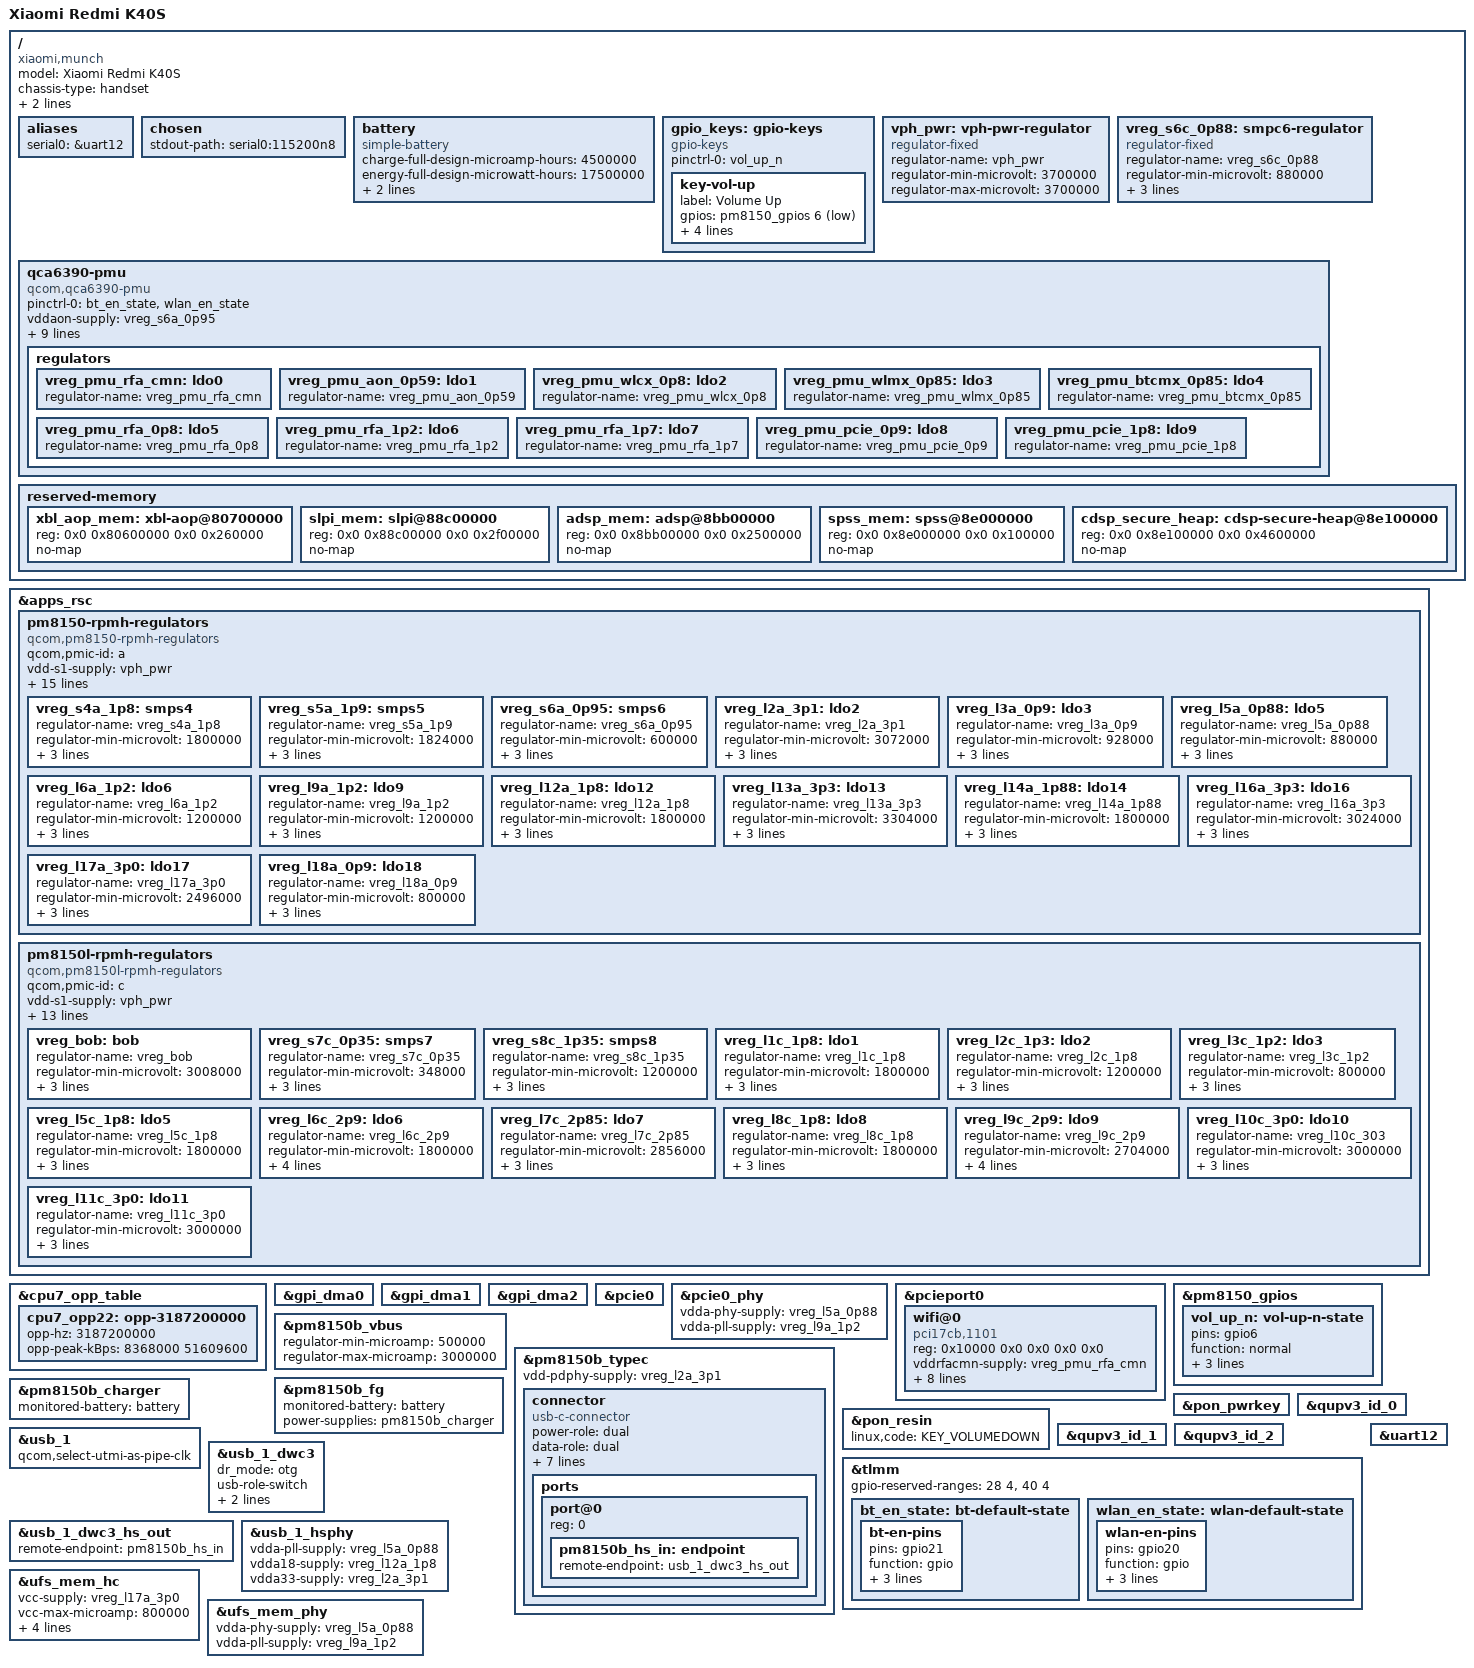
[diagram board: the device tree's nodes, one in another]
// SPDX-License-Identifier: GPL-2.0-only OR BSD-2-Clause
/*
 * Xiaomi Redmi K40S (munch) — headless server device tree
 *
 * Minimal device tree for running the K40S as a screenless Linux server:
 * only the peripherals relevant to headless operation are enabled.
 *
 *   kept:    UFS storage, USB (gadget / USB-C role switch), PCIe QCA6390 WiFi,
 *            PMIC charging + fuel gauge, volume keys, UART debug console,
 *            CPU OPP (incl. SM8250-AC boost clock), RPMH regulators.
 *   removed: display panel/DSI, touch, cameras, audio, GPU, video codec,
 *            NFC, IR LED, sensors, wireless charging, remoteproc firmware.
 *
 * Board-level values were derived from the Xiaomi POCO F3 (alioth) mainline
 * port (Copyright (c) 2025 Vitalii Skorkin) — same SM8250-AC platform and
 * PMIC wiring — and cross-checked against the LineageOS munch vendor device
 * tree (battery capacity, UFS rails, WiFi/BT enable GPIOs, AOP memory map).
 */

/dts-v1/;

#include <dt-bindings/arm/qcom,ids.h>
#include <dt-bindings/regulator/qcom,rpmh-regulator.h>
#include <dt-bindings/usb/pd.h>
#include "sm8250.dtsi"
#include "pm8150.dtsi"
#include "pm8150b.dtsi"
#include "pm8150l.dtsi"

/*
 * Delete following upstream (sm8250.dtsi) reserved
 * memory mappings which are different on this device.
 */
/delete-node/ &adsp_mem;
/delete-node/ &cdsp_secure_heap;
/delete-node/ &slpi_mem;
/delete-node/ &spss_mem;
/delete-node/ &xbl_aop_mem;

/ {

	model = "Xiaomi Redmi K40S";
	compatible = "xiaomi,munch", "qcom,sm8250";
	chassis-type = "handset";

	/* required for bootloader to select correct board */
	qcom,msm-id = <QCOM_ID_SM8250 0x20001>; /* SM8250 v2.1 */
	qcom,board-id = <50 0>;

	aliases {
		serial0 = &uart12;
	};

	chosen {
		#address-cells = <2>;
		#size-cells = <2>;
		ranges;
		stdout-path = "serial0:115200n8";
	};

	battery: battery {
		compatible = "simple-battery";
		charge-full-design-microamp-hours = <4500000>;
		energy-full-design-microwatt-hours = <17500000>;
		voltage-min-design-microvolt = <3400000>;
		voltage-max-design-microvolt = <4460000>;
	};

	gpio_keys: gpio-keys {
		compatible = "gpio-keys";

		pinctrl-0 = <&vol_up_n>;
		pinctrl-names = "default";

		key-vol-up {
			label = "Volume Up";
			gpios = <&pm8150_gpios 6 GPIO_ACTIVE_LOW>;
			linux,code = <KEY_VOLUMEUP>;
			debounce-interval = <15>;
			linux,can-disable;
			wakeup-source;
		};
	};

	vph_pwr: vph-pwr-regulator {
		compatible = "regulator-fixed";
		regulator-name = "vph_pwr";
		regulator-min-microvolt = <3700000>;
		regulator-max-microvolt = <3700000>;
	};

	/* S6c is really ebi.lvl but it's there for supply map completeness sake. */
	vreg_s6c_0p88: smpc6-regulator {
		compatible = "regulator-fixed";
		regulator-name = "vreg_s6c_0p88";
		regulator-min-microvolt = <880000>;
		regulator-max-microvolt = <880000>;
		regulator-always-on;
		vin-supply = <&vph_pwr>;
	};

	qca6390-pmu {
		compatible = "qcom,qca6390-pmu";

		pinctrl-names = "default";
		pinctrl-0 = <&bt_en_state>, <&wlan_en_state>;

		vddaon-supply = <&vreg_s6a_0p95>;
		vddpmu-supply = <&vreg_s6a_0p95>;
		vddrfa0p95-supply = <&vreg_s6a_0p95>;
		vddrfa1p3-supply = <&vreg_s8c_1p35>;
		vddrfa1p9-supply = <&vreg_s5a_1p9>;
		vddpcie1p3-supply = <&vreg_s8c_1p35>;
		vddpcie1p9-supply = <&vreg_s5a_1p9>;
		vddio-supply = <&vreg_s4a_1p8>;

		wlan-enable-gpios = <&tlmm 20 GPIO_ACTIVE_HIGH>;
		bt-enable-gpios = <&tlmm 21 GPIO_ACTIVE_HIGH>;

		regulators {
			vreg_pmu_rfa_cmn: ldo0 {
				regulator-name = "vreg_pmu_rfa_cmn";
			};

			vreg_pmu_aon_0p59: ldo1 {
				regulator-name = "vreg_pmu_aon_0p59";
			};

			vreg_pmu_wlcx_0p8: ldo2 {
				regulator-name = "vreg_pmu_wlcx_0p8";
			};

			vreg_pmu_wlmx_0p85: ldo3 {
				regulator-name = "vreg_pmu_wlmx_0p85";
			};

			vreg_pmu_btcmx_0p85: ldo4 {
				regulator-name = "vreg_pmu_btcmx_0p85";
			};

			vreg_pmu_rfa_0p8: ldo5 {
				regulator-name = "vreg_pmu_rfa_0p8";
			};

			vreg_pmu_rfa_1p2: ldo6 {
				regulator-name = "vreg_pmu_rfa_1p2";
			};

			vreg_pmu_rfa_1p7: ldo7 {
				regulator-name = "vreg_pmu_rfa_1p7";
			};

			vreg_pmu_pcie_0p9: ldo8 {
				regulator-name = "vreg_pmu_pcie_0p9";
			};

			vreg_pmu_pcie_1p8: ldo9 {
				regulator-name = "vreg_pmu_pcie_1p8";
			};
		};
	};

	reserved-memory {
		xbl_aop_mem: xbl-aop@80700000 {
			reg = <0x0 0x80600000 0x0 0x260000>;
			no-map;
		};

		slpi_mem: slpi@88c00000 {
			reg = <0x0 0x88c00000 0x0 0x2f00000>;
			no-map;
		};

		adsp_mem: adsp@8bb00000 {
			reg = <0x0 0x8bb00000 0x0 0x2500000>;
			no-map;
		};

		spss_mem: spss@8e000000 {
			reg = <0x0 0x8e000000 0x0 0x100000>;
			no-map;
		};

		cdsp_secure_heap: cdsp-secure-heap@8e100000 {
			reg = <0x0 0x8e100000 0x0 0x4600000>;
			no-map;
		};
	};
};

/*
 * RPMH regulators: platform wiring shared by Xiaomi SM8250 boards.
 * Kept in full — these rails are consumed by UFS, USB, PCIe/WiFi,
 * the QCA6390 PMU tree and the PMIC charger.
 */
&apps_rsc {
	pm8150-rpmh-regulators {
		compatible = "qcom,pm8150-rpmh-regulators";
		qcom,pmic-id = "a";

		vdd-s1-supply = <&vph_pwr>;
		vdd-s2-supply = <&vph_pwr>;
		vdd-s3-supply = <&vph_pwr>;
		vdd-s4-supply = <&vph_pwr>;
		vdd-s5-supply = <&vph_pwr>;
		vdd-s6-supply = <&vph_pwr>;
		vdd-s7-supply = <&vph_pwr>;
		vdd-s8-supply = <&vph_pwr>;
		vdd-s9-supply = <&vph_pwr>;
		vdd-s10-supply = <&vph_pwr>;
		vdd-l1-l8-l11-supply = <&vreg_s6c_0p88>;
		vdd-l2-l10-supply = <&vreg_bob>;
		vdd-l3-l4-l5-l18-supply = <&vreg_s6a_0p95>;
		vdd-l6-l9-supply = <&vreg_s8c_1p35>;
		vdd-l7-l12-l14-l15-supply = <&vreg_s5a_1p9>;
		vdd-l13-l16-l17-supply = <&vreg_bob>;

		/* (S1+S2+S3) - cx.lvl (ARC) */

		vreg_s4a_1p8: smps4 {
			regulator-name = "vreg_s4a_1p8";
			regulator-min-microvolt = <1800000>;
			regulator-max-microvolt = <1920000>;
			regulator-initial-mode = <RPMH_REGULATOR_MODE_HPM>;
		};

		vreg_s5a_1p9: smps5 {
			regulator-name = "vreg_s5a_1p9";
			regulator-min-microvolt = <1824000>;
			regulator-max-microvolt = <2040000>;
			regulator-initial-mode = <RPMH_REGULATOR_MODE_HPM>;
		};

		vreg_s6a_0p95: smps6 {
			regulator-name = "vreg_s6a_0p95";
			regulator-min-microvolt = <600000>;
			regulator-max-microvolt = <1128000>;
			regulator-initial-mode = <RPMH_REGULATOR_MODE_HPM>;
		};

		vreg_l2a_3p1: ldo2 {
			regulator-name = "vreg_l2a_3p1";
			regulator-min-microvolt = <3072000>;
			regulator-max-microvolt = <3072000>;
			regulator-initial-mode = <RPMH_REGULATOR_MODE_HPM>;
		};

		vreg_l3a_0p9: ldo3 {
			regulator-name = "vreg_l3a_0p9";
			regulator-min-microvolt = <928000>;
			regulator-max-microvolt = <932000>;
			regulator-initial-mode = <RPMH_REGULATOR_MODE_HPM>;
		};

		/* L4 - lmx.lvl (ARC) */

		vreg_l5a_0p88: ldo5 {
			regulator-name = "vreg_l5a_0p88";
			regulator-min-microvolt = <880000>;
			regulator-max-microvolt = <880000>;
			regulator-initial-mode = <RPMH_REGULATOR_MODE_HPM>;
		};

		vreg_l6a_1p2: ldo6 {
			regulator-name = "vreg_l6a_1p2";
			regulator-min-microvolt = <1200000>;
			regulator-max-microvolt = <1200000>;
			regulator-initial-mode = <RPMH_REGULATOR_MODE_HPM>;
		};

		vreg_l9a_1p2: ldo9 {
			regulator-name = "vreg_l9a_1p2";
			regulator-min-microvolt = <1200000>;
			regulator-max-microvolt = <1200000>;
			regulator-initial-mode = <RPMH_REGULATOR_MODE_HPM>;
		};

		vreg_l12a_1p8: ldo12 {
			regulator-name = "vreg_l12a_1p8";
			regulator-min-microvolt = <1800000>;
			regulator-max-microvolt = <1800000>;
			regulator-initial-mode = <RPMH_REGULATOR_MODE_HPM>;
		};

		vreg_l13a_3p3: ldo13 {
			regulator-name = "vreg_l13a_3p3";
			regulator-min-microvolt = <3304000>;
			regulator-max-microvolt = <3304000>;
			regulator-initial-mode = <RPMH_REGULATOR_MODE_HPM>;
		};

		vreg_l14a_1p88: ldo14 {
			regulator-name = "vreg_l14a_1p88";
			regulator-min-microvolt = <1800000>;
			regulator-max-microvolt = <1880000>;
			regulator-initial-mode = <RPMH_REGULATOR_MODE_HPM>;
		};

		vreg_l16a_3p3: ldo16 {
			regulator-name = "vreg_l16a_3p3";
			regulator-min-microvolt = <3024000>;
			regulator-max-microvolt = <3304000>;
			regulator-initial-mode = <RPMH_REGULATOR_MODE_HPM>;
		};

		vreg_l17a_3p0: ldo17 {
			regulator-name = "vreg_l17a_3p0";
			regulator-min-microvolt = <2496000>;
			regulator-max-microvolt = <3008000>;
			regulator-initial-mode = <RPMH_REGULATOR_MODE_HPM>;
		};

		vreg_l18a_0p9: ldo18 {
			regulator-name = "vreg_l18a_0p9";
			regulator-min-microvolt = <800000>;
			regulator-max-microvolt = <920000>;
			regulator-initial-mode = <RPMH_REGULATOR_MODE_HPM>;
		};
	};

	pm8150l-rpmh-regulators {
		compatible = "qcom,pm8150l-rpmh-regulators";
		qcom,pmic-id = "c";

		vdd-s1-supply = <&vph_pwr>;
		vdd-s2-supply = <&vph_pwr>;
		vdd-s3-supply = <&vph_pwr>;
		vdd-s4-supply = <&vph_pwr>;
		vdd-s5-supply = <&vph_pwr>;
		vdd-s6-supply = <&vph_pwr>;
		vdd-s7-supply = <&vph_pwr>;
		vdd-s8-supply = <&vph_pwr>;
		vdd-l1-l8-supply = <&vreg_s4a_1p8>;
		vdd-l2-l3-supply = <&vreg_s8c_1p35>;
		vdd-l4-l5-l6-supply = <&vreg_bob>;
		vdd-l7-l11-supply = <&vreg_bob>;
		vdd-l9-l10-supply = <&vreg_bob>;
		vdd-bob-supply = <&vph_pwr>;

		vreg_bob: bob {
			regulator-name = "vreg_bob";
			regulator-min-microvolt = <3008000>;
			regulator-max-microvolt = <3960000>;
			regulator-initial-mode = <RPMH_REGULATOR_MODE_AUTO>;
		};

		/*
		 * S1-S6 are ARCs:
		 * (S1+S2) - gfx.lvl,
		 * S3 - mx.lvl,
		 * (S4+S5) - mmcx.lvl,
		 * S6 - ebi.lvl
		 */

		vreg_s7c_0p35: smps7 {
			regulator-name = "vreg_s7c_0p35";
			regulator-min-microvolt = <348000>;
			regulator-max-microvolt = <1000000>;
			regulator-initial-mode = <RPMH_REGULATOR_MODE_HPM>;
		};

		vreg_s8c_1p35: smps8 {
			regulator-name = "vreg_s8c_1p35";
			regulator-min-microvolt = <1200000>;
			regulator-max-microvolt = <1400000>;
			regulator-initial-mode = <RPMH_REGULATOR_MODE_HPM>;
		};

		vreg_l1c_1p8: ldo1 {
			regulator-name = "vreg_l1c_1p8";
			regulator-min-microvolt = <1800000>;
			regulator-max-microvolt = <1800000>;
			regulator-initial-mode = <RPMH_REGULATOR_MODE_HPM>;
		};

		vreg_l2c_1p3: ldo2 {
			regulator-name = "vreg_l2c_1p8";
			regulator-min-microvolt = <1200000>;
			regulator-max-microvolt = <1304000>;
			regulator-initial-mode = <RPMH_REGULATOR_MODE_HPM>;
		};

		vreg_l3c_1p2: ldo3 {
			regulator-name = "vreg_l3c_1p2";
			regulator-min-microvolt = <800000>;
			regulator-max-microvolt = <1200000>;
			regulator-initial-mode = <RPMH_REGULATOR_MODE_HPM>;
		};

		vreg_l5c_1p8: ldo5 {
			regulator-name = "vreg_l5c_1p8";
			regulator-min-microvolt = <1800000>;
			regulator-max-microvolt = <2800000>;
			regulator-initial-mode = <RPMH_REGULATOR_MODE_HPM>;
		};

		vreg_l6c_2p9: ldo6 {
			regulator-name = "vreg_l6c_2p9";
			regulator-min-microvolt = <1800000>;
			regulator-max-microvolt = <2960000>;
			regulator-initial-mode = <RPMH_REGULATOR_MODE_HPM>;
			regulator-allow-set-load;
		};

		vreg_l7c_2p85: ldo7 {
			regulator-name = "vreg_l7c_2p85";
			regulator-min-microvolt = <2856000>;
			regulator-max-microvolt = <3104000>;
			regulator-initial-mode = <RPMH_REGULATOR_MODE_HPM>;
		};

		vreg_l8c_1p8: ldo8 {
			regulator-name = "vreg_l8c_1p8";
			regulator-min-microvolt = <1800000>;
			regulator-max-microvolt = <1800000>;
			regulator-initial-mode = <RPMH_REGULATOR_MODE_HPM>;
		};

		vreg_l9c_2p9: ldo9 {
			regulator-name = "vreg_l9c_2p9";
			regulator-min-microvolt = <2704000>;
			regulator-max-microvolt = <2960000>;
			regulator-initial-mode = <RPMH_REGULATOR_MODE_HPM>;
			regulator-allow-set-load;
		};

		vreg_l10c_3p0: ldo10 {
			regulator-name = "vreg_l10c_303";
			regulator-min-microvolt = <3000000>;
			regulator-max-microvolt = <3312000>;
			regulator-initial-mode = <RPMH_REGULATOR_MODE_HPM>;
		};

		vreg_l11c_3p0: ldo11 {
			regulator-name = "vreg_l11c_3p0";
			regulator-min-microvolt = <3000000>;
			regulator-max-microvolt = <3000000>;
			regulator-initial-mode = <RPMH_REGULATOR_MODE_HPM>;
		};
	};
};

/* SM8250-AC ("SD870") boost clock: 3.1872 GHz */
&cpu7_opp_table {
	cpu7_opp22: opp-3187200000 {
		opp-hz = /bits/ 64 <3187200000>;
		opp-peak-kBps = <8368000 51609600>;
	};
};

&gpi_dma0 {
	status = "okay";
};

&gpi_dma1 {
	status = "okay";
};

&gpi_dma2 {
	status = "okay";
};

/* --- WiFi: QCA6390 on PCIe0 --- */

&pcie0 {
	status = "okay";
};

&pcie0_phy {
	vdda-phy-supply = <&vreg_l5a_0p88>;
	vdda-pll-supply = <&vreg_l9a_1p2>;
	status = "okay";
};

&pcieport0 {
	wifi@0 {
		compatible = "pci17cb,1101";
		reg = <0x10000 0x0 0x0 0x0 0x0>;

		vddrfacmn-supply = <&vreg_pmu_rfa_cmn>;
		vddaon-supply = <&vreg_pmu_aon_0p59>;
		vddwlcx-supply = <&vreg_pmu_wlcx_0p8>;
		vddwlmx-supply = <&vreg_pmu_wlmx_0p85>;
		vddrfa0p8-supply = <&vreg_pmu_rfa_0p8>;
		vddrfa1p2-supply = <&vreg_pmu_rfa_1p2>;
		vddrfa1p7-supply = <&vreg_pmu_rfa_1p7>;
		vddpcie0p9-supply = <&vreg_pmu_pcie_0p9>;
		vddpcie1p8-supply = <&vreg_pmu_pcie_1p8>;
	};
};

/* --- Power / keys / charging --- */

&pm8150_gpios {
	vol_up_n: vol-up-n-state {
		pins = "gpio6";
		function = "normal";
		power-source = <1>;
		input-enable;
		bias-pull-up;
	};
};

&pm8150b_vbus {
	regulator-min-microamp = <500000>;
	regulator-max-microamp = <3000000>;
	status = "okay";
};

&pm8150b_typec {
	status = "okay";

	vdd-pdphy-supply = <&vreg_l2a_3p1>;

	connector {
		compatible = "usb-c-connector";

		power-role = "dual";
		data-role = "dual";
		try-power-role = "sink";
		self-powered;

		op-sink-microwatt = <33000000>;

		source-pdos = <PDO_FIXED(5000, 3000,
					  PDO_FIXED_DUAL_ROLE |
					  PDO_FIXED_USB_COMM |
					  PDO_FIXED_DATA_SWAP)>;

		sink-pdos = <PDO_FIXED(5000, 3000,
					   PDO_FIXED_DUAL_ROLE |
					   PDO_FIXED_USB_COMM |
					   PDO_FIXED_DATA_SWAP)
					   PDO_VAR(5000, 9000, 3500)>;

		ports {
			#address-cells = <1>;
			#size-cells = <0>;

			port@0 {
				reg = <0>;
				pm8150b_hs_in: endpoint {
					remote-endpoint = <&usb_1_dwc3_hs_out>;
				};
			};
		};
	};
};

&pm8150b_fg {
	status = "okay";
	monitored-battery = <&battery>;
	power-supplies = <&pm8150b_charger>;
};

&pm8150b_charger {
	status = "okay";
	monitored-battery = <&battery>;
};

&pon_pwrkey {
	status = "okay";
};

&pon_resin {
	linux,code = <KEY_VOLUMEDOWN>;
	status = "okay";
};

/* --- QUP wrappers (UART console on qupv3_id_1/uart12) --- */

&qupv3_id_0 {
	status = "okay";
};

&qupv3_id_1 {
	status = "okay";
};

&qupv3_id_2 {
	status = "okay";
};

/* --- TLMM: WiFi/BT enable pins --- */

&tlmm {
	gpio-reserved-ranges = <28 4>, <40 4>;

	bt_en_state: bt-default-state {
		bt-en-pins {
			pins = "gpio21";
			function = "gpio";
			drive-strength = <16>;
			output-low;
			bias-pull-up;
		};
	};

	wlan_en_state: wlan-default-state {
		wlan-en-pins {
			pins = "gpio20";
			function = "gpio";
			drive-strength = <16>;
			output-low;
			bias-pull-up;
		};
	};
};

/* --- Debug UART (pins/clock provided by sm8250.dtsi) --- */

&uart12 {
	status = "okay";
};

/* --- USB: USB 2.0 gadget, Type-C role switch --- */

&usb_1 {
	/* USB 2.0 only */
	qcom,select-utmi-as-pipe-clk;
	status = "okay";
};

&usb_1_dwc3 {
	dr_mode = "otg";
	usb-role-switch;
	maximum-speed = "high-speed";
	/* Remove USB3 phy */
	phys = <&usb_1_hsphy>;
	phy-names = "usb2-phy";
};

&usb_1_dwc3_hs_out {
	remote-endpoint = <&pm8150b_hs_in>;
};

&usb_1_hsphy {
	vdda-pll-supply = <&vreg_l5a_0p88>;
	vdda18-supply = <&vreg_l12a_1p8>;
	vdda33-supply = <&vreg_l2a_3p1>;
	status = "okay";
};

/* --- UFS 3.1 --- */

&ufs_mem_hc {
	vcc-supply = <&vreg_l17a_3p0>;
	vcc-max-microamp = <800000>;
	vccq-supply = <&vreg_l6a_1p2>;
	vccq-max-microamp = <800000>;
	vccq2-supply = <&vreg_s4a_1p8>;
	vccq2-max-microamp = <800000>;
	status = "okay";
};

&ufs_mem_phy {
	vdda-phy-supply = <&vreg_l5a_0p88>;
	vdda-pll-supply = <&vreg_l9a_1p2>;
	status = "okay";
};
